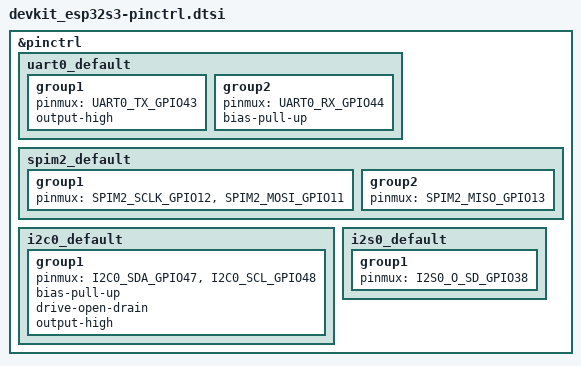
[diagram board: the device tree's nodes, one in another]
/*
* Copyright (c) 2026 FoBE Studio
*
* SPDX-License-Identifier: Apache-2.0
*/

#include <zephyr/dt-bindings/pinctrl/esp-pinctrl-common.h>
#include <dt-bindings/pinctrl/esp32s3-pinctrl.h>
#include <zephyr/dt-bindings/pinctrl/esp32s3-gpio-sigmap.h>

&pinctrl {
	uart0_default: uart0_default {
		group1 {
			pinmux = <UART0_TX_GPIO43>;
			output-high;
		};
		group2 {
			pinmux = <UART0_RX_GPIO44>;
			bias-pull-up;
		};
	};

	spim2_default: spim2_default {
		group1 {
			pinmux = <SPIM2_SCLK_GPIO12>,
			         <SPIM2_MOSI_GPIO11>;
		};
		
		group2 {
			pinmux = <SPIM2_MISO_GPIO13>;
		};
	};
	
	i2c0_default: i2c0_default {
		group1 {
			pinmux = <I2C0_SDA_GPIO47>,
			<I2C0_SCL_GPIO48>;
			bias-pull-up;
			drive-open-drain;
			output-high;
		};
	};
	
	i2s0_default: i2s0_default {
		group1 {
			pinmux = <I2S0_O_SD_GPIO38>;
		};
	};
};
